# SKEAZN642 register map
Vendor: Freescale Semiconductor, Inc.; File version: 1.6
CPU: CM0PLUS r0p0, little endian, no MPU, no FPU, 0x2 interrupt priority bits, 0x0 interrupts
Registers are 32-bit, read-write, reset 0x0 unless marked. A register's access mark holds for its fields unless they carry their own. Offsets are from the block's base; [hi:lo] are bit positions; 'fields as' and 'values as' point back to an identical list.

## PIT — Periodic Interrupt Timer
Base 0x40037000; register names take the prefix PIT_
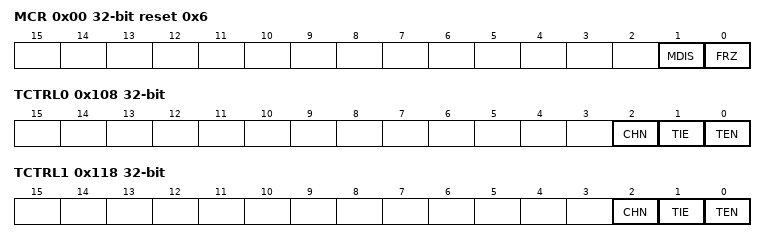
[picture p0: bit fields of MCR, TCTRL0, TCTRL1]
0x00 MCR reset 0x6 — PIT Module Control Register
  [1] MDIS — Module Disable - (PIT section)
    0=Clock for standard PIT timers is enabled; 1=Clock for standard PIT timers is disabled
  [0] FRZ — Freeze
    0=Timers continue to run in Debug mode; 1=Timers are stopped in Debug mode
0x100 LDVAL0 — Timer Load Value Register
  [31:0] TSV — Timer Start Value
0x104 CVAL0 ro — Current Timer Value Register
  [31:0] TVL — Current Timer Value
0x108 TCTRL0 — Timer Control Register
  [2] CHN — Chain Mode
    0=Timer is not chained; 1=Timer is chained to previous timer. For example, for Channel 2, if this field is set, Timer 2 is chained to Timer 1.
  [1] TIE — Timer Interrupt Enable
    0=Interrupt requests from Timer n are disabled; 1=Interrupt will be requested whenever TIF is set
  [0] TEN — Timer Enable
    0=Timer n is disabled; 1=Timer n is enabled
0x10C TFLG0 — Timer Flag Register
  [0] TIF — Timer Interrupt Flag
    0=Timeout has not yet occurred; 1=Timeout has occurred
0x110 LDVAL1 — Timer Load Value Register
  [31:0] TSV — Timer Start Value
0x114 CVAL1 ro — Current Timer Value Register
  [31:0] TVL — Current Timer Value
0x118 TCTRL1 — Timer Control Register
  fields as TCTRL0
0x11C TFLG1 — Timer Flag Register
  fields as TFLG0

## FTM0 — FlexTimer Module
Base 0x40038000; register names take the prefix FTM0_
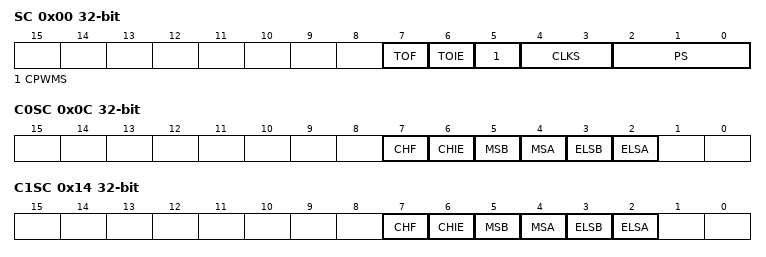
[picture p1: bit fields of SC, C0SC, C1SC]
0x00 SC — Status And Control
  [7] TOF ro — Timer Overflow Flag
    0=FTM counter has not overflowed; 1=FTM counter has overflowed
  [6] TOIE — Timer Overflow Interrupt Enable
    0=Disable TOF interrupts. Use software polling.; 1=Enable TOF interrupts. An interrupt is generated when TOF equals one.
  [5] CPWMS — Center-Aligned PWM Select
    0=FTM counter operates in Up Counting mode; 1=FTM counter operates in Up-Down Counting mode
  [4:3] CLKS — Clock Source Selection
    0=No clock selected. This in effect disables the FTM counter.; 1=System clock; 2=Fixed frequency clock; 3=External clock
  [2:0] PS — Prescale Factor Selection
    0=Divide by 1; 1=Divide by 2; 2=Divide by 4; 3=Divide by 8; 4=Divide by 16; 5=Divide by 32; 6=Divide by 64; 7=Divide by 128
0x04 CNT — Counter
  [15:0] COUNT — Counter Value
0x08 MOD — Modulo
  [15:0] MOD
0x0C C0SC — Channel (n) Status And Control
  [7] CHF ro — Channel Flag
    0=No channel event has occurred; 1=A channel event has occurred
  [6] CHIE — Channel Interrupt Enable
    0=Disable channel interrupts. Use software polling.; 1=Enable channel interrupts
  [5] MSB — Channel Mode Select
  [4] MSA — Channel Mode Select
  [3] ELSB — Edge or Level Select
  [2] ELSA — Edge or Level Select
0x10 C0V — Channel (n) Value
  [15:0] VAL — Channel Value
0x14 C1SC — Channel (n) Status And Control
  fields as C0SC
0x18 C1V — Channel (n) Value
  [15:0] VAL — Channel Value

## FTM1 — FlexTimer Module
Base 0x40039000; register names take the prefix FTM1_
Registers as FTM0.

## RTC — Real-time counter
Base 0x4003D000; register names take the prefix RTC_
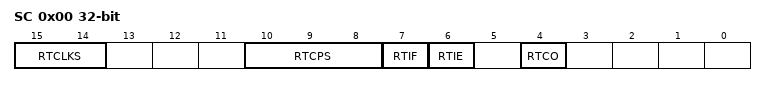
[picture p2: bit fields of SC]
0x00 SC — RTC Status and Control Register
  [15:14] RTCLKS — Real-Time Clock Source Select
    0=External clock source; 1=Real-time clock source is 1 kHz (LPOCLK); 2=Internal reference clock (ICSIRCLK); 3=Bus clock
  [10:8] RTCPS — Real-Time Clock Prescaler Select
    0=Off; 1=If RTCLKS = x0, it is 1; if RTCLKS = x1, it is 128; 2=If RTCLKS = x0, it is 2; if RTCLKS = x1, it is 256; 3=If RTCLKS = x0, it is 4; if RTCLKS = x1, it is 512; 4=If RTCLKS = x0, it is 8; if RTCLKS = x1, it is 1024; 5=If RTCLKS = x0, it is 16; if RTCLKS = x1, it is 2048; 6=If RTCLKS = x0, it is 32; if RTCLKS = x1, it is 100; 7=If RTCLKS = x0, it is 64; if RTCLKS = x1, it is 1000
  [7] RTIF — Real-Time Interrupt Flag
    0=RTC counter has not reached the value in the RTC modulo register; 1=RTC counter has reached the value in the RTC modulo register
  [6] RTIE — Real-Time Interrupt Enable
    0=Real-time interrupt requests are disabled. Use software polling.; 1=Real-time interrupt requests are enabled
  [4] RTCO — Real-Time Counter Output
    0=Real-time counter output disabled; 1=Real-time counter output enabled
0x04 MOD — RTC Modulo Register
  [15:0] MOD — RTC Modulo
0x08 CNT ro — RTC Counter Register
  [15:0] CNT — RTC Count
